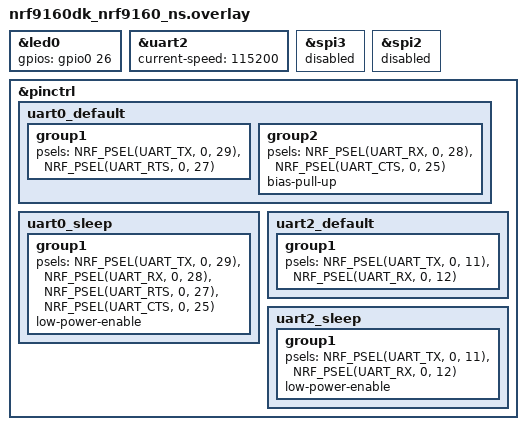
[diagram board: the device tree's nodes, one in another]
// To get started, press Ctrl+Space to bring up the completion menu and view the available nodes.

// You can also use the buttons in the sidebar to perform actions on nodes.
// Actions currently available include:

// * Enabling / disabling the node
// * Adding the bus to a bus
// * Removing the node
// * Connecting ADC channels

// For more help, browse the DeviceTree documentation at https://docs.zephyrproject.org/latest/guides/dts/index.html
// You can also visit the nRF DeviceTree extension documentation at https://nrfconnect.github.io/vscode-nrf-connect/devicetree/nrfdevicetree.html

&led0{
    gpios = <&gpio0 26 0>;
};

&uart2 {
	status = "okay";
	current-speed = <115200>;
};

arduino_spi: &spi3 {
	status = "disabled";
};

&spi2 {
	status = "disabled";
};


&pinctrl {
	uart0_default: uart0_default {
		group1 {
			psels = <NRF_PSEL(UART_TX, 0, 29)>,
				<NRF_PSEL(UART_RTS, 0, 27)>;
		};
		group2 {
			psels = <NRF_PSEL(UART_RX, 0, 28)>,
				<NRF_PSEL(UART_CTS, 0, 25)>;
			bias-pull-up;
		};
	};

	uart0_sleep: uart0_sleep {
		group1 {
			psels = <NRF_PSEL(UART_TX, 0, 29)>,
				<NRF_PSEL(UART_RX, 0, 28)>,
				<NRF_PSEL(UART_RTS, 0, 27)>,
				<NRF_PSEL(UART_CTS, 0, 25)>;
			low-power-enable;
		};
	};

	uart2_default: uart2_default {
		group1 {
			psels = <NRF_PSEL(UART_TX, 0, 11)>,
				<NRF_PSEL(UART_RX, 0, 12)>;
		};
	};

	uart2_sleep: uart2_sleep {
		group1 {
			psels = <NRF_PSEL(UART_TX, 0, 11)>,
				<NRF_PSEL(UART_RX, 0, 12)>;
			low-power-enable;
		};
	};
};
